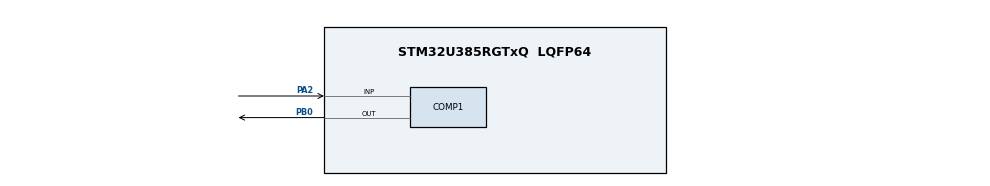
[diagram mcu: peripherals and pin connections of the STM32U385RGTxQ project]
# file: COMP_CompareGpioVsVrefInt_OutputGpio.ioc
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COMP1.Hysteresis=COMP_HYSTERESIS_MEDIUM
CORTEX_M33_NS.userName=CORTEX_M33
Mcu.Family=STM32U3
Mcu.Name=STM32U385RGTxQ
Mcu.Package=LQFP64
NVIC.PriorityGroup=NVIC_PRIORITYGROUP_4
PA2.Mode=INP
PA2.Signal=COMP1_INP
PB0.Mode=ExternalOutput
PB0.Signal=COMP1_OUT
ProjectManager.HeapSize=0x200
ProjectManager.StackSize=0x400
ProjectManager.TargetToolchain=EWARM V9.20
RCC.ADCFreq_Value=96000000
RCC.AHBFreq_Value=96000000
RCC.APB1Freq_Value=96000000
RCC.APB1TimFreq_Value=96000000
RCC.APB2Freq_Value=96000000
RCC.APB2TimFreq_Value=96000000
RCC.APB3Freq_Value=96000000
RCC.CortexFreq_Value=12000000
RCC.HCLKFreq_Value=96000000
RCC.HSE_VALUE=16000000
RCC.HSI48_VALUE=48000000
RCC.HSI_VALUE=16000000
RCC.LSE_VALUE=32768
RCC.LSIDIV_VALUE=32000
RCC.MSISDIV=RCC_MSI_DIV1
RCC.SYSCLKFreq_VALUE=96000000
RCC.USBFreq_Value=96000000
VP_COMP1_VS_VREFINT.Mode=VREFINT
VP_ICACHE_VS_ICACHE.Mode=DirectMappedCache
VP_PWR_VS_DBSignals.Mode=DisableDeadBatterySignals
VP_PWR_VS_LPOM.Mode=PowerOptimisation
VP_PWR_VS_SECSignals.Mode=Security/Privilege
board=custom

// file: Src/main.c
/* USER CODE BEGIN Header */
/**
  ******************************************************************************
  * @file    Examples/COMP/COMP_CompareGpioVsVrefInt_OutputGpio/Src/main.c
  * @author  MCD Application Team
  * @brief   How to use a comparator peripheral to compare a voltage level
  *          on a GPIO pin versus the internal voltage reference (VrefInt)
  *          with comparator output connected to a GPIO pin.
  *          This example is based on the STM32U3xx COMP HAL API.
  ******************************************************************************
  * @attention
  *
  * Copyright (c) 2024 STMicroelectronics.
  * All rights reserved.
  *
  * This software is licensed under terms that can be found in the LICENSE file
  * in the root directory of this software component.
  * If no LICENSE file comes with this software, it is provided AS-IS.
  *
  ******************************************************************************
  */
/* USER CODE END Header */
#include "main.h"

COMP_HandleTypeDef hcomp1;

void SystemClock_Config(void);
static void MX_GPIO_Init(void);
static void MX_COMP1_Init(void);
static void MX_ICACHE_Init(void);

int main(void)
{

  /* MCU Configuration--------------------------------------------------------*/

  /* Reset of all peripherals, Initializes the Flash interface and the Systick. */
  HAL_Init();

  /* Configure the system clock */
  SystemClock_Config();

  /* Initialize all configured peripherals */
  MX_GPIO_Init();
  MX_COMP1_Init();
  MX_ICACHE_Init();
  /* USER CODE BEGIN 2 */
  BSP_LED_Init(LD2);

  /* Start comparator */
  if(HAL_COMP_Start(&hcomp1) != HAL_OK)
  {
    /* Initialization Error */
    Error_Handler();
  }

  /* Lock comparator instance */
  /* Note: Comparator lock is optional, to protect against any unexpected
           program action on comparator configuration
           (for example, due to program counter corruption). */
  //HAL_COMP_Lock(&hcomp1);

  /* USER CODE END 2 */

  /* Infinite loop */
  /* USER CODE BEGIN WHILE */
  while (1)
  {
    /* Set LED state in function of state of GPIO connected to                */
    /* comparator output.                                                     */
    /* Note: State of GPIO is monitored for the purpose of this example.      */
    /*       An alternate solution is to monitor directly comparator output   */
    /*       using function "HAL_COMP_GetOutputLevel()".                      */
    if (HAL_GPIO_ReadPin(GPIOB, GPIO_PIN_0) != 0)
    {
      BSP_LED_On(LD2);
    }
    else
    {
      BSP_LED_Off(LD2);
    }

    /* USER CODE END WHILE */

  }
}

void SystemClock_Config(void)
{
  RCC_OscInitTypeDef RCC_OscInitStruct = {0};
  RCC_ClkInitTypeDef RCC_ClkInitStruct = {0};

  /** Enable Epod Booster
  */
  if (HAL_RCCEx_EpodBoosterClkConfig(RCC_EPODBOOSTER_SOURCE_MSIS, RCC_EPODBOOSTER_DIV1) != HAL_OK)
  {
    Error_Handler();
  }

  if (HAL_PWREx_EnableEpodBooster() != HAL_OK)
  {
    Error_Handler();
  }

  /** Configure the main internal regulator output voltage
  */
  if (HAL_PWREx_ControlVoltageScaling(PWR_REGULATOR_VOLTAGE_SCALE1) != HAL_OK)
  {
    Error_Handler();
  }

  /** Set Flash latency before increasing MSIS
  */
  __HAL_FLASH_SET_LATENCY(FLASH_LATENCY_2);

  /** Initializes the CPU, AHB and APB buses clocks
  */
  RCC_OscInitStruct.OscillatorType = RCC_OSCILLATORTYPE_MSIS;
  RCC_OscInitStruct.MSISState = RCC_MSI_ON;
  RCC_OscInitStruct.MSISSource = RCC_MSI_RC0;
  RCC_OscInitStruct.MSISDiv = RCC_MSI_DIV1;
  if (HAL_RCC_OscConfig(&RCC_OscInitStruct) != HAL_OK)
  {
    Error_Handler();
  }

  /** Initializes the CPU, AHB and APB buses clocks
  */
  RCC_ClkInitStruct.ClockType = RCC_CLOCKTYPE_HCLK|RCC_CLOCKTYPE_SYSCLK
                              |RCC_CLOCKTYPE_PCLK1|RCC_CLOCKTYPE_PCLK2
                              |RCC_CLOCKTYPE_PCLK3;
  RCC_ClkInitStruct.SYSCLKSource = RCC_SYSCLKSOURCE_MSIS;
  RCC_ClkInitStruct.AHBCLKDivider = RCC_SYSCLK_DIV1;
  RCC_ClkInitStruct.APB1CLKDivider = RCC_HCLK_DIV1;
  RCC_ClkInitStruct.APB2CLKDivider = RCC_HCLK_DIV1;
  RCC_ClkInitStruct.APB3CLKDivider = RCC_HCLK_DIV1;

  if (HAL_RCC_ClockConfig(&RCC_ClkInitStruct, FLASH_LATENCY_2) != HAL_OK)
  {
    Error_Handler();
  }
}

static void MX_COMP1_Init(void)
{

  hcomp1.Instance = COMP1;
  hcomp1.Init.InputPlus = COMP_INPUT_PLUS_IO3;
  hcomp1.Init.InputMinus = COMP_INPUT_MINUS_VREFINT;
  hcomp1.Init.OutputPol = COMP_OUTPUTPOL_NONINVERTED;
  hcomp1.Init.WindowOutput = COMP_WINDOWOUTPUT_EACH_COMP;
  hcomp1.Init.Hysteresis = COMP_HYSTERESIS_MEDIUM;
  hcomp1.Init.BlankingSrce = COMP_BLANKINGSRC_NONE;
  hcomp1.Init.Mode = COMP_POWERMODE_HIGHSPEED;
  hcomp1.Init.WindowMode = COMP_WINDOWMODE_DISABLE;
  hcomp1.Init.TriggerMode = COMP_TRIGGERMODE_NONE;
  if (HAL_COMP_Init(&hcomp1) != HAL_OK)
  {
    Error_Handler();
  }

}

static void MX_ICACHE_Init(void)
{

  /** Enable instruction cache in 1-way (direct mapped cache)
  */
  if (HAL_ICACHE_ConfigAssociativityMode(ICACHE_1WAY) != HAL_OK)
  {
    Error_Handler();
  }
  if (HAL_ICACHE_Enable() != HAL_OK)
  {
    Error_Handler();
  }

}

static void MX_GPIO_Init(void)
{

  /* GPIO Ports Clock Enable */
  __HAL_RCC_GPIOA_CLK_ENABLE();
  __HAL_RCC_GPIOB_CLK_ENABLE();

}

void Error_Handler(void)
{
  /* USER CODE BEGIN Error_Handler_Debug */
  /* User can add his own implementation to report the HAL error return state */

  /* Turn on LED and remain in infinite loop */
  while (1)
  {
    BSP_LED_On(LD2);
  }
  /* USER CODE END Error_Handler_Debug */
}
